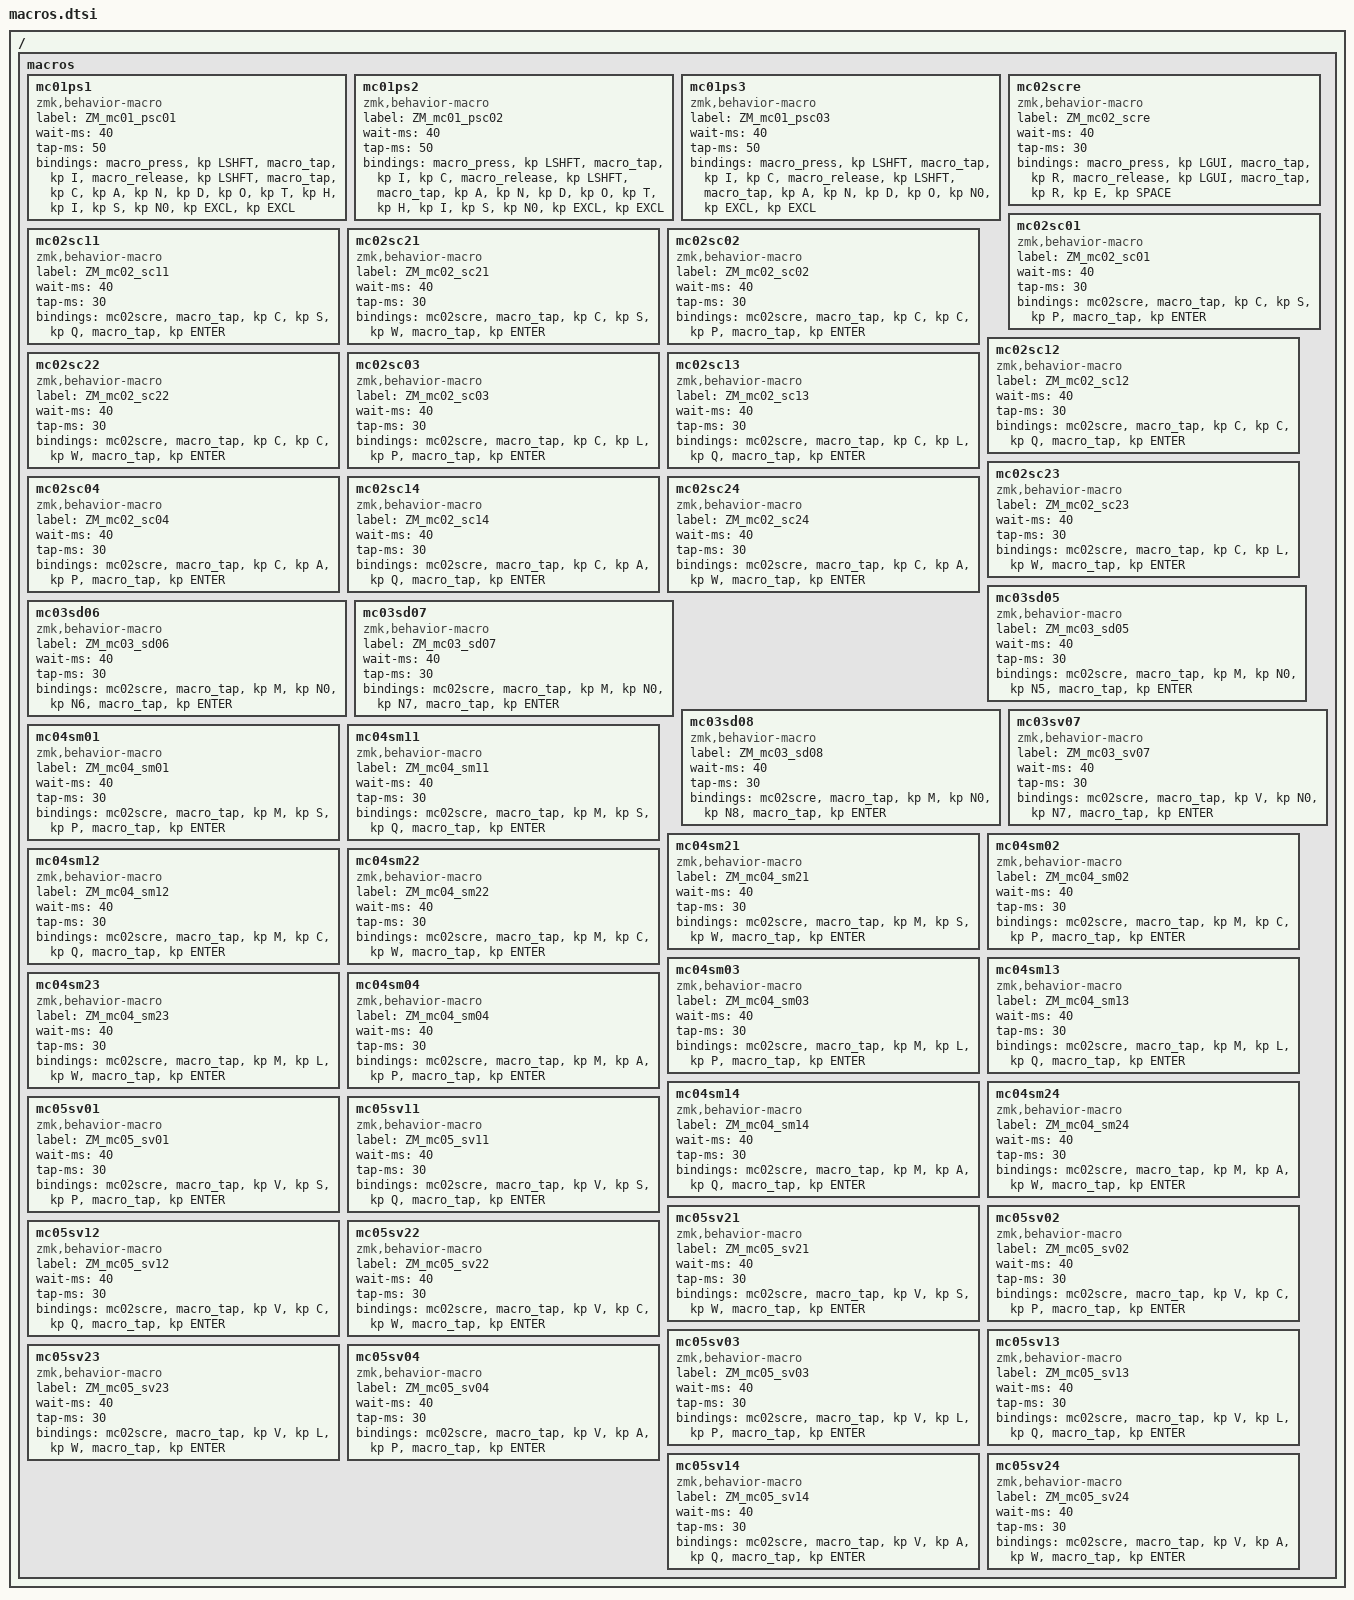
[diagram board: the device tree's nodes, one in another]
/ {
    
    macros {

        /* Macros ps */
        mc01ps1: mc01ps1 {
            label = "ZM_mc01_psc01";
            compatible = "zmk,behavior-macro";
            #binding-cells = <0>;
            wait-ms = <40>;
            tap-ms = <50>;
            bindings
                = <&macro_press &kp LSHFT>
                , <&macro_tap &kp I>
                , <&macro_release &kp LSHFT>
                , <&macro_tap &kp C &kp A &kp N &kp D &kp O &kp T &kp H &kp I &kp S &kp N0 &kp EXCL &kp EXCL>
                ;
        };

        mc01ps2: mc01ps2 {
            label = "ZM_mc01_psc02";
            compatible = "zmk,behavior-macro";
            #binding-cells = <0>;
            wait-ms = <40>;
            tap-ms = <50>;
            bindings
                = <&macro_press &kp LSHFT>
                , <&macro_tap &kp I &kp C>
                , <&macro_release &kp LSHFT>
                , <&macro_tap &kp A &kp N &kp D &kp O &kp T &kp H &kp I &kp S &kp N0 &kp EXCL &kp EXCL>
                ;
        };

        mc01ps3: mc01ps3 {
            label = "ZM_mc01_psc03";
            compatible = "zmk,behavior-macro";
            #binding-cells = <0>;
            wait-ms = <40>;
            tap-ms = <50>;
            bindings
                = <&macro_press &kp LSHFT>
                , <&macro_tap &kp I &kp C>
                , <&macro_release &kp LSHFT>
                , <&macro_tap &kp A &kp N &kp D &kp O &kp N0 &kp EXCL &kp EXCL>
                ;
        };

        /**************************
         Macro to execute programs 
        **************************/
        mc02scre: mc02scre {
            label = "ZM_mc02_scre";
            compatible = "zmk,behavior-macro";
            #binding-cells = <0>;
            wait-ms = <40>;
            tap-ms = <30>;
            bindings
                = <&macro_press &kp LGUI>
                , <&macro_tap &kp R>
                , <&macro_release &kp LGUI>
                , <&macro_tap &kp R &kp E &kp SPACE>
                ;
        };

        /***********************
         Macros to execute curo 
        ***********************/
        mc02sc01: mc02sc01 {
            label = "ZM_mc02_sc01";
            compatible = "zmk,behavior-macro";
            #binding-cells = <0>;
            wait-ms = <40>;
            tap-ms = <30>;
            bindings
                = <&mc02scre>
                , <&macro_tap &kp C &kp S &kp P>
                , <&macro_tap &kp ENTER>
                ;
        };

        mc02sc11: mc02sc11 {
            label = "ZM_mc02_sc11";
            compatible = "zmk,behavior-macro";
            #binding-cells = <0>;
            wait-ms = <40>;
            tap-ms = <30>;
            bindings
                = <&mc02scre>
                , <&macro_tap &kp C &kp S &kp Q>
                , <&macro_tap &kp ENTER>
                ;
        };

         mc02sc21: mc02sc21 {
            label = "ZM_mc02_sc21";
            compatible = "zmk,behavior-macro";
            #binding-cells = <0>;
            wait-ms = <40>;
            tap-ms = <30>;
            bindings
                = <&mc02scre>
                , <&macro_tap &kp C &kp S &kp W>
                , <&macro_tap &kp ENTER>
                ;
        };

        mc02sc02: mc02sc02 {
            label = "ZM_mc02_sc02";
            compatible = "zmk,behavior-macro";
            #binding-cells = <0>;
            wait-ms = <40>;
            tap-ms = <30>;
            bindings
                = <&mc02scre>
                , <&macro_tap &kp C &kp C &kp P>
                , <&macro_tap &kp ENTER>
                ;
        };

        mc02sc12: mc02sc12 {
            label = "ZM_mc02_sc12";
            compatible = "zmk,behavior-macro";
            #binding-cells = <0>;
            wait-ms = <40>;
            tap-ms = <30>;
            bindings
                = <&mc02scre>
                , <&macro_tap &kp C &kp C &kp Q>
                , <&macro_tap &kp ENTER>
                ;
        };

        mc02sc22: mc02sc22 {
            label = "ZM_mc02_sc22";
            compatible = "zmk,behavior-macro";
            #binding-cells = <0>;
            wait-ms = <40>;
            tap-ms = <30>;
            bindings
                = <&mc02scre>
                , <&macro_tap &kp C &kp C &kp W>
                , <&macro_tap &kp ENTER>
                ;
        };

        mc02sc03: mc02sc03 {
            label = "ZM_mc02_sc03";
            compatible = "zmk,behavior-macro";
            #binding-cells = <0>;
            wait-ms = <40>;
            tap-ms = <30>;
            bindings
                = <&mc02scre>
                , <&macro_tap &kp C &kp L &kp P>
                , <&macro_tap &kp ENTER>
                ;
        };

        mc02sc13: mc02sc13 {
            label = "ZM_mc02_sc13";
            compatible = "zmk,behavior-macro";
            #binding-cells = <0>;
            wait-ms = <40>;
            tap-ms = <30>;
            bindings
                = <&mc02scre>
                , <&macro_tap &kp C &kp L &kp Q>
                , <&macro_tap &kp ENTER>
                ;
        };

        mc02sc23: mc02sc23 {
            label = "ZM_mc02_sc23";
            compatible = "zmk,behavior-macro";
            #binding-cells = <0>;
            wait-ms = <40>;
            tap-ms = <30>;
            bindings
                = <&mc02scre>
                , <&macro_tap &kp C &kp L &kp W>
                , <&macro_tap &kp ENTER>
                ;
        };

        mc02sc04: mc02sc04 {
            label = "ZM_mc02_sc04";
            compatible = "zmk,behavior-macro";
            #binding-cells = <0>;
            wait-ms = <40>;
            tap-ms = <30>;
            bindings
                = <&mc02scre>
                , <&macro_tap &kp C &kp A &kp P>
                , <&macro_tap &kp ENTER>
                ;
        };

        mc02sc14: mc02sc14 {
            label = "ZM_mc02_sc14";
            compatible = "zmk,behavior-macro";
            #binding-cells = <0>;
            wait-ms = <40>;
            tap-ms = <30>;
            bindings
                = <&mc02scre>
                , <&macro_tap &kp C &kp A &kp Q>
                , <&macro_tap &kp ENTER>
                ;
        };

        mc02sc24: mc02sc24 {
            label = "ZM_mc02_sc24";
            compatible = "zmk,behavior-macro";
            #binding-cells = <0>;
            wait-ms = <40>;
            tap-ms = <30>;
            bindings
                = <&mc02scre>
                , <&macro_tap &kp C &kp A &kp W>
                , <&macro_tap &kp ENTER>
                ;
        };

        /***********************
         Macros to open servers 
        ***********************/
        mc03sd05: mc03sd05 {
            label = "ZM_mc03_sd05";
            compatible = "zmk,behavior-macro";
            #binding-cells = <0>;
            wait-ms = <40>;
            tap-ms = <30>;
            bindings
                = <&mc02scre>
                , <&macro_tap &kp M &kp N0 &kp N5>
                , <&macro_tap &kp ENTER>
                ;
        };

        mc03sd06: mc03sd06 {
            label = "ZM_mc03_sd06";
            compatible = "zmk,behavior-macro";
            #binding-cells = <0>;
            wait-ms = <40>;
            tap-ms = <30>;
            bindings
                = <&mc02scre>
                , <&macro_tap &kp M &kp N0 &kp N6>
                , <&macro_tap &kp ENTER>
                ;
        };

        mc03sd07: mc03sd07 {
            label = "ZM_mc03_sd07";
            compatible = "zmk,behavior-macro";
            #binding-cells = <0>;
            wait-ms = <40>;
            tap-ms = <30>;
            bindings
                = <&mc02scre>
                , <&macro_tap &kp M &kp N0 &kp N7>
                , <&macro_tap &kp ENTER>
                ;
        };

        mc03sd08: mc03sd08 {
            label = "ZM_mc03_sd08";
            compatible = "zmk,behavior-macro";
            #binding-cells = <0>;
            wait-ms = <40>;
            tap-ms = <30>;
            bindings
                = <&mc02scre>
                , <&macro_tap &kp M &kp N0 &kp N8>
                , <&macro_tap &kp ENTER>
                ;
        };

        mc03sv07: mc03sv07 {
            label = "ZM_mc03_sv07";
            compatible = "zmk,behavior-macro";
            #binding-cells = <0>;
            wait-ms = <40>;
            tap-ms = <30>;
            bindings
                = <&mc02scre>
                , <&macro_tap &kp V &kp N0 &kp N7>
                , <&macro_tap &kp ENTER>
                ;
        };

        /*****************************
        Macros to open Scoring Manager
        *****************************/
        mc04sm01: mc04sm01 {
            label = "ZM_mc04_sm01";
            compatible = "zmk,behavior-macro";
            #binding-cells = <0>;
            wait-ms = <40>;
            tap-ms = <30>;
            bindings
                = <&mc02scre>
                , <&macro_tap &kp M &kp S &kp P>
                , <&macro_tap &kp ENTER>
                ;
        };

        mc04sm11: mc04sm11 {
            label = "ZM_mc04_sm11";
            compatible = "zmk,behavior-macro";
            #binding-cells = <0>;
            wait-ms = <40>;
            tap-ms = <30>;
            bindings
                = <&mc02scre>
                , <&macro_tap &kp M &kp S &kp Q>
                , <&macro_tap &kp ENTER>
                ;
        };

        mc04sm21: mc04sm21 {
            label = "ZM_mc04_sm21";
            compatible = "zmk,behavior-macro";
            #binding-cells = <0>;
            wait-ms = <40>;
            tap-ms = <30>;
            bindings
                = <&mc02scre>
                , <&macro_tap &kp M &kp S &kp W>
                , <&macro_tap &kp ENTER>
                ;
        };

        mc04sm02: mc04sm02 {
            label = "ZM_mc04_sm02";
            compatible = "zmk,behavior-macro";
            #binding-cells = <0>;
            wait-ms = <40>;
            tap-ms = <30>;
            bindings
                = <&mc02scre>
                , <&macro_tap &kp M &kp C &kp P>
                , <&macro_tap &kp ENTER>
                ;
        };

        mc04sm12: mc04sm12 {
            label = "ZM_mc04_sm12";
            compatible = "zmk,behavior-macro";
            #binding-cells = <0>;
            wait-ms = <40>;
            tap-ms = <30>;
            bindings
                = <&mc02scre>
                , <&macro_tap &kp M &kp C &kp Q>
                , <&macro_tap &kp ENTER>
                ;
        };

        mc04sm22: mc04sm22 {
            label = "ZM_mc04_sm22";
            compatible = "zmk,behavior-macro";
            #binding-cells = <0>;
            wait-ms = <40>;
            tap-ms = <30>;
            bindings
                = <&mc02scre>
                , <&macro_tap &kp M &kp C &kp W>
                , <&macro_tap &kp ENTER>
                ;
        };

        mc04sm03: mc04sm03 {
            label = "ZM_mc04_sm03";
            compatible = "zmk,behavior-macro";
            #binding-cells = <0>;
            wait-ms = <40>;
            tap-ms = <30>;
            bindings
                = <&mc02scre>
                , <&macro_tap &kp M &kp L &kp P>
                , <&macro_tap &kp ENTER>
                ;
        };

        mc04sm13: mc04sm13 {
            label = "ZM_mc04_sm13";
            compatible = "zmk,behavior-macro";
            #binding-cells = <0>;
            wait-ms = <40>;
            tap-ms = <30>;
            bindings
                = <&mc02scre>
                , <&macro_tap &kp M &kp L &kp Q>
                , <&macro_tap &kp ENTER>
                ;
        };

        mc04sm23: mc04sm23 {
            label = "ZM_mc04_sm23";
            compatible = "zmk,behavior-macro";
            #binding-cells = <0>;
            wait-ms = <40>;
            tap-ms = <30>;
            bindings
                = <&mc02scre>
                , <&macro_tap &kp M &kp L &kp W>
                , <&macro_tap &kp ENTER>
                ;
        };

        mc04sm04: mc04sm04 {
            label = "ZM_mc04_sm04";
            compatible = "zmk,behavior-macro";
            #binding-cells = <0>;
            wait-ms = <40>;
            tap-ms = <30>;
            bindings
                = <&mc02scre>
                , <&macro_tap &kp M &kp A &kp P>
                , <&macro_tap &kp ENTER>
                ;
        };

        mc04sm14: mc04sm14 {
            label = "ZM_mc04_sm14";
            compatible = "zmk,behavior-macro";
            #binding-cells = <0>;
            wait-ms = <40>;
            tap-ms = <30>;
            bindings
                = <&mc02scre>
                , <&macro_tap &kp M &kp A &kp Q>
                , <&macro_tap &kp ENTER>
                ;
        };

        mc04sm24: mc04sm24 {
            label = "ZM_mc04_sm24";
            compatible = "zmk,behavior-macro";
            #binding-cells = <0>;
            wait-ms = <40>;
            tap-ms = <30>;
            bindings
                = <&mc02scre>
                , <&macro_tap &kp M &kp A &kp W>
                , <&macro_tap &kp ENTER>
                ;
        };

        /*****************************
        Macros to open Scoring Viewer
        *****************************/
        mc05sv01: mc05sv01 {
            label = "ZM_mc05_sv01";
            compatible = "zmk,behavior-macro";
            #binding-cells = <0>;
            wait-ms = <40>;
            tap-ms = <30>;
            bindings
                = <&mc02scre>
                , <&macro_tap &kp V &kp S &kp P>
                , <&macro_tap &kp ENTER>
                ;
        };

        mc05sv11: mc05sv11 {
            label = "ZM_mc05_sv11";
            compatible = "zmk,behavior-macro";
            #binding-cells = <0>;
            wait-ms = <40>;
            tap-ms = <30>;
            bindings
                = <&mc02scre>
                , <&macro_tap &kp V &kp S &kp Q>
                , <&macro_tap &kp ENTER>
                ;
        };

        mc05sv21: mc05sv21 {
            label = "ZM_mc05_sv21";
            compatible = "zmk,behavior-macro";
            #binding-cells = <0>;
            wait-ms = <40>;
            tap-ms = <30>;
            bindings
                = <&mc02scre>
                , <&macro_tap &kp V &kp S &kp W>
                , <&macro_tap &kp ENTER>
                ;
        };

        mc05sv02: mc05sv02 {
            label = "ZM_mc05_sv02";
            compatible = "zmk,behavior-macro";
            #binding-cells = <0>;
            wait-ms = <40>;
            tap-ms = <30>;
            bindings
                = <&mc02scre>
                , <&macro_tap &kp V &kp C &kp P>
                , <&macro_tap &kp ENTER>
                ;
        };

        mc05sv12: mc05sv12 {
            label = "ZM_mc05_sv12";
            compatible = "zmk,behavior-macro";
            #binding-cells = <0>;
            wait-ms = <40>;
            tap-ms = <30>;
            bindings
                = <&mc02scre>
                , <&macro_tap &kp V &kp C &kp Q>
                , <&macro_tap &kp ENTER>
                ;
        };

        mc05sv22: mc05sv22 {
            label = "ZM_mc05_sv22";
            compatible = "zmk,behavior-macro";
            #binding-cells = <0>;
            wait-ms = <40>;
            tap-ms = <30>;
            bindings
                = <&mc02scre>
                , <&macro_tap &kp V &kp C &kp W>
                , <&macro_tap &kp ENTER>
                ;
        };

        mc05sv03: mc05sv03 {
            label = "ZM_mc05_sv03";
            compatible = "zmk,behavior-macro";
            #binding-cells = <0>;
            wait-ms = <40>;
            tap-ms = <30>;
            bindings
                = <&mc02scre>
                , <&macro_tap &kp V &kp L &kp P>
                , <&macro_tap &kp ENTER>
                ;
        };

        mc05sv13: mc05sv13 {
            label = "ZM_mc05_sv13";
            compatible = "zmk,behavior-macro";
            #binding-cells = <0>;
            wait-ms = <40>;
            tap-ms = <30>;
            bindings
                = <&mc02scre>
                , <&macro_tap &kp V &kp L &kp Q>
                , <&macro_tap &kp ENTER>
                ;
        };

        mc05sv23: mc05sv23 {
            label = "ZM_mc05_sv23";
            compatible = "zmk,behavior-macro";
            #binding-cells = <0>;
            wait-ms = <40>;
            tap-ms = <30>;
            bindings
                = <&mc02scre>
                , <&macro_tap &kp V &kp L &kp W>
                , <&macro_tap &kp ENTER>
                ;
        };

        mc05sv04: mc05sv04 {
            label = "ZM_mc05_sv04";
            compatible = "zmk,behavior-macro";
            #binding-cells = <0>;
            wait-ms = <40>;
            tap-ms = <30>;
            bindings
                = <&mc02scre>
                , <&macro_tap &kp V &kp A &kp P>
                , <&macro_tap &kp ENTER>
                ;
        };

        mc05sv14: mc05sv14 {
            label = "ZM_mc05_sv14";
            compatible = "zmk,behavior-macro";
            #binding-cells = <0>;
            wait-ms = <40>;
            tap-ms = <30>;
            bindings
                = <&mc02scre>
                , <&macro_tap &kp V &kp A &kp Q>
                , <&macro_tap &kp ENTER>
                ;
        };

        mc05sv24: mc05sv24 {
            label = "ZM_mc05_sv24";
            compatible = "zmk,behavior-macro";
            #binding-cells = <0>;
            wait-ms = <40>;
            tap-ms = <30>;
            bindings
                = <&mc02scre>
                , <&macro_tap &kp V &kp A &kp W>
                , <&macro_tap &kp ENTER>
                ;
        };

    };
};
